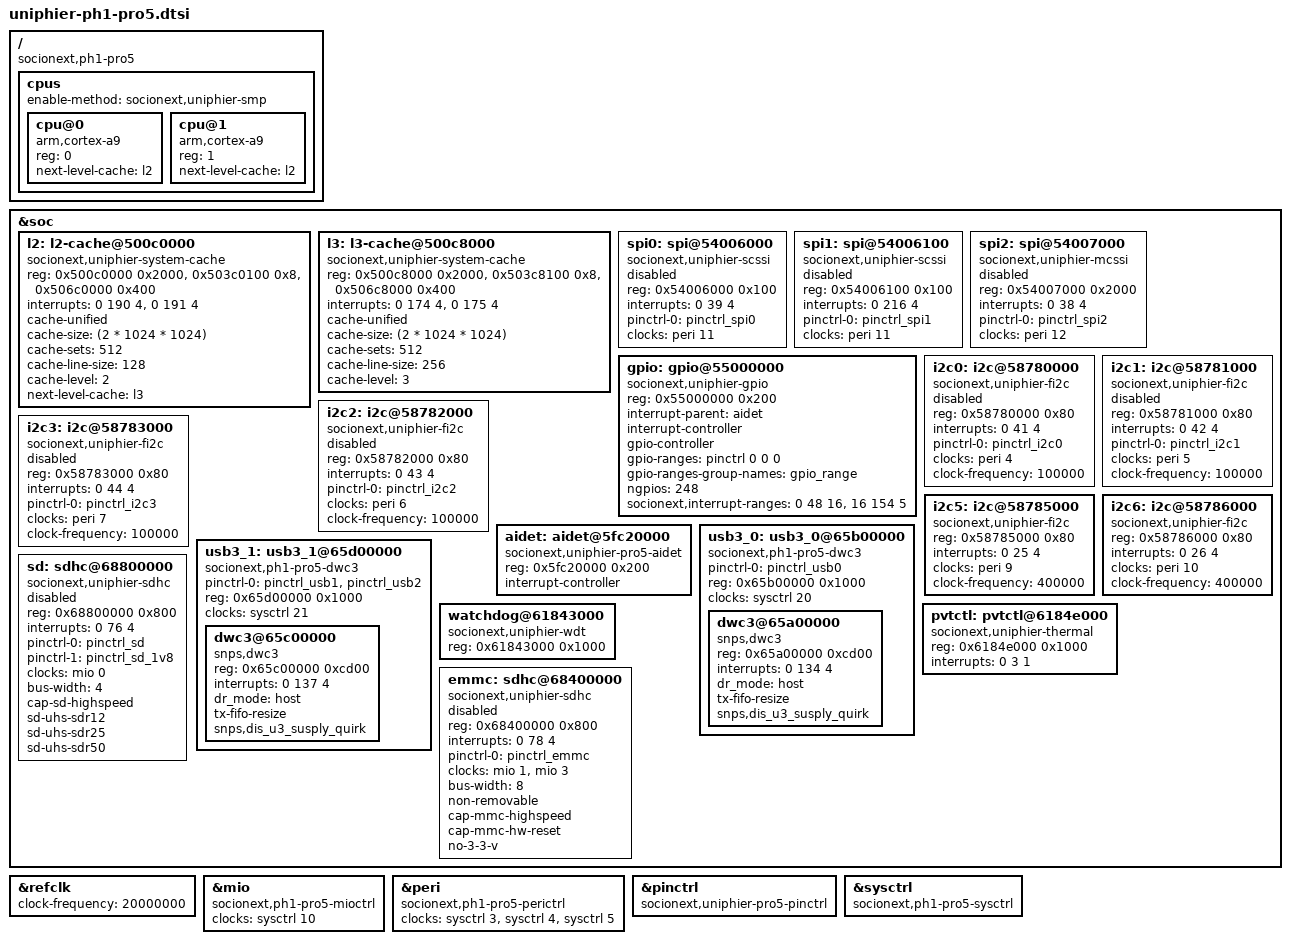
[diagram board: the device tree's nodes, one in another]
// SPDX-License-Identifier: GPL-2.0+ OR MIT
//
// Device Tree Source for UniPhier PH1-Pro5 SoC
//
// Copyright (C) 2015-2016 Socionext Inc.
//   Author: Masahiro Yamada <yamada.masahiro@socionext.com>

#include "uniphier-common32.dtsi"

/ {
	compatible = "socionext,ph1-pro5";

	cpus {
		#address-cells = <1>;
		#size-cells = <0>;
		enable-method = "socionext,uniphier-smp";

		cpu@0 {
			device_type = "cpu";
			compatible = "arm,cortex-a9";
			reg = <0>;
			next-level-cache = <&l2>;
		};

		cpu@1 {
			device_type = "cpu";
			compatible = "arm,cortex-a9";
			reg = <1>;
			next-level-cache = <&l2>;
		};
	};
};

&soc {
	l2: l2-cache@500c0000 {
		compatible = "socionext,uniphier-system-cache";
		reg = <0x500c0000 0x2000>, <0x503c0100 0x8>, <0x506c0000 0x400>;
		interrupts = <0 190 4>, <0 191 4>;
		cache-unified;
		cache-size = <(2 * 1024 * 1024)>;
		cache-sets = <512>;
		cache-line-size = <128>;
		cache-level = <2>;
		next-level-cache = <&l3>;
	};

	l3: l3-cache@500c8000 {
		compatible = "socionext,uniphier-system-cache";
		reg = <0x500c8000 0x2000>, <0x503c8100 0x8>, <0x506c8000 0x400>;
		interrupts = <0 174 4>, <0 175 4>;
		cache-unified;
		cache-size = <(2 * 1024 * 1024)>;
		cache-sets = <512>;
		cache-line-size = <256>;
		cache-level = <3>;
	};

	spi0: spi@54006000 {
		compatible = "socionext,uniphier-scssi";
		status = "disabled";
		reg = <0x54006000 0x100>;
		interrupts = <0 39 4>;
		pinctrl-names = "default";
		pinctrl-0 = <&pinctrl_spi0>;
		clocks = <&peri 11>;
	};

	spi1: spi@54006100 {
		compatible = "socionext,uniphier-scssi";
		status = "disabled";
		reg = <0x54006100 0x100>;
		interrupts = <0 216 4>;
		pinctrl-names = "default";
		pinctrl-0 = <&pinctrl_spi1>;
		clocks = <&peri 11>;
	};

	spi2: spi@54007000 {
		compatible = "socionext,uniphier-mcssi";
		status = "disabled";
		reg = <0x54007000 0x2000>;
		interrupts = <0 38 4>;
		pinctrl-names = "default";
		pinctrl-0 = <&pinctrl_spi2>;
		clocks = <&peri 12>;
	};

	gpio: gpio@55000000 {
		compatible = "socionext,uniphier-gpio";
		reg = <0x55000000 0x200>;
		interrupt-parent = <&aidet>;
		interrupt-controller;
		#interrupt-cells = <2>;
		gpio-controller;
		#gpio-cells = <2>;
		gpio-ranges = <&pinctrl 0 0 0>;
		gpio-ranges-group-names = "gpio_range";
		ngpios = <248>;
		socionext,interrupt-ranges = <0 48 16>, <16 154 5>;
	};

	i2c0: i2c@58780000 {
		compatible = "socionext,uniphier-fi2c";
		status = "disabled";
		reg = <0x58780000 0x80>;
		#address-cells = <1>;
		#size-cells = <0>;
		interrupts = <0 41 4>;
		pinctrl-names = "default";
		pinctrl-0 = <&pinctrl_i2c0>;
		clocks = <&peri 4>;
		clock-frequency = <100000>;
	};

	i2c1: i2c@58781000 {
		compatible = "socionext,uniphier-fi2c";
		status = "disabled";
		reg = <0x58781000 0x80>;
		#address-cells = <1>;
		#size-cells = <0>;
		interrupts = <0 42 4>;
		pinctrl-names = "default";
		pinctrl-0 = <&pinctrl_i2c1>;
		clocks = <&peri 5>;
		clock-frequency = <100000>;
	};

	i2c2: i2c@58782000 {
		compatible = "socionext,uniphier-fi2c";
		status = "disabled";
		reg = <0x58782000 0x80>;
		#address-cells = <1>;
		#size-cells = <0>;
		interrupts = <0 43 4>;
		pinctrl-names = "default";
		pinctrl-0 = <&pinctrl_i2c2>;
		clocks = <&peri 6>;
		clock-frequency = <100000>;
	};

	i2c3: i2c@58783000 {
		compatible = "socionext,uniphier-fi2c";
		status = "disabled";
		reg = <0x58783000 0x80>;
		#address-cells = <1>;
		#size-cells = <0>;
		interrupts = <0 44 4>;
		pinctrl-names = "default";
		pinctrl-0 = <&pinctrl_i2c3>;
		clocks = <&peri 7>;
		clock-frequency = <100000>;
	};

	/* i2c4 does not exist */

	/* chip-internal connection for DMD */
	i2c5: i2c@58785000 {
		compatible = "socionext,uniphier-fi2c";
		reg = <0x58785000 0x80>;
		#address-cells = <1>;
		#size-cells = <0>;
		interrupts = <0 25 4>;
		clocks = <&peri 9>;
		clock-frequency = <400000>;
	};

	/* chip-internal connection for HDMI */
	i2c6: i2c@58786000 {
		compatible = "socionext,uniphier-fi2c";
		reg = <0x58786000 0x80>;
		#address-cells = <1>;
		#size-cells = <0>;
		interrupts = <0 26 4>;
		clocks = <&peri 10>;
		clock-frequency = <400000>;
	};

	aidet: aidet@5fc20000 {
		compatible = "socionext,uniphier-pro5-aidet";
		reg = <0x5fc20000 0x200>;
		interrupt-controller;
		#interrupt-cells = <2>;
	};

	usb3_0: usb3_0@65b00000 {
		compatible = "socionext,ph1-pro5-dwc3";
		status = "okay";
		pinctrl-names = "default";
		pinctrl-0 = <&pinctrl_usb0>;
		reg = <0x65b00000 0x1000>;
		clocks = <&sysctrl 20>;
		clock-names = "u3clk0";
		#address-cells = <1>;
		#size-cells = <1>;
		ranges;
		dwc3@65a00000 {
			compatible = "snps,dwc3";
			reg = <0x65a00000 0xcd00>;
			interrupts = <0 134 4>;
			dr_mode = "host";
			tx-fifo-resize;
			snps,dis_u3_susply_quirk;
		};
	};

	usb3_1: usb3_1@65d00000 {
		compatible = "socionext,ph1-pro5-dwc3";
		status = "okay";
		pinctrl-names = "default";
		pinctrl-0 = <&pinctrl_usb1>, <&pinctrl_usb2>;
		reg = <0x65d00000 0x1000>;
		clocks = <&sysctrl 21>;
		clock-names = "u3clk0";
		#address-cells = <1>;
		#size-cells = <1>;
		ranges;
		dwc3@65c00000 {
			compatible = "snps,dwc3";
			reg = <0x65c00000 0xcd00>;
			interrupts = <0 137 4>;
			dr_mode = "host";
			tx-fifo-resize;
			snps,dis_u3_susply_quirk;
		};
	};

	watchdog@61843000 {
		compatible = "socionext,uniphier-wdt";
		reg = <0x61843000 0x1000>;
	};

	pvtctl: pvtctl@6184e000 {
		compatible = "socionext,uniphier-thermal";
		reg = <0x6184e000 0x1000>;
		interrupts = <0 3 1>;
		#thermal-sensor-cells = <0>;
	};

	emmc: sdhc@68400000 {
		compatible = "socionext,uniphier-sdhc";
		status = "disabled";
		reg = <0x68400000 0x800>;
		interrupts = <0 78 4>;
		pinctrl-names = "default";
		pinctrl-0 = <&pinctrl_emmc>;
		clock-names = "host", "hw-reset";
		clocks = <&mio 1>, <&mio 3>;
		bus-width = <8>;
		non-removable;
		cap-mmc-highspeed;
		cap-mmc-hw-reset;
		no-3-3-v;
	};

	sd: sdhc@68800000 {
		compatible = "socionext,uniphier-sdhc";
		status = "disabled";
		reg = <0x68800000 0x800>;
		interrupts = <0 76 4>;
		pinctrl-names = "default", "1.8v";
		pinctrl-0 = <&pinctrl_sd>;
		pinctrl-1 = <&pinctrl_sd_1v8>;
		clock-names = "host";
		clocks = <&mio 0>;
		bus-width = <4>;
		cap-sd-highspeed;
		sd-uhs-sdr12;
		sd-uhs-sdr25;
		sd-uhs-sdr50;
	};
};

&refclk {
	clock-frequency = <20000000>;
};

&mio {
	compatible = "socionext,ph1-pro5-mioctrl";
	clock-names = "stdmac";
	clocks = <&sysctrl 10>;
};

&peri {
	compatible = "socionext,ph1-pro5-perictrl";
	clock-names = "uart", "fi2c", "spi";
	clocks = <&sysctrl 3>, <&sysctrl 4>, <&sysctrl 5>;
};

&pinctrl {
	compatible = "socionext,uniphier-pro5-pinctrl";
};

&sysctrl {
	compatible = "socionext,ph1-pro5-sysctrl";
};
